# EFM32GG11B840F1024IQ100 register map
File version: 4.0.0
CPU: CM4 r0p1, little endian, MPU, FPU, 3 interrupt priority bits
Registers are 32-bit, read-write, reset 0x0 unless marked. A register's access mark holds for its fields unless they carry their own. Offsets are from the block's base; [hi:lo] are bit positions; {n}, {i} and the like mark numbered series.

## USART0
Base 0x40010000
Same registers: USART1 0x40010400, USART2 0x40010800, USART3 0x40010C00, USART4 0x40011000, USART5 0x40011400, UART0 0x40014000, UART1 0x40014400
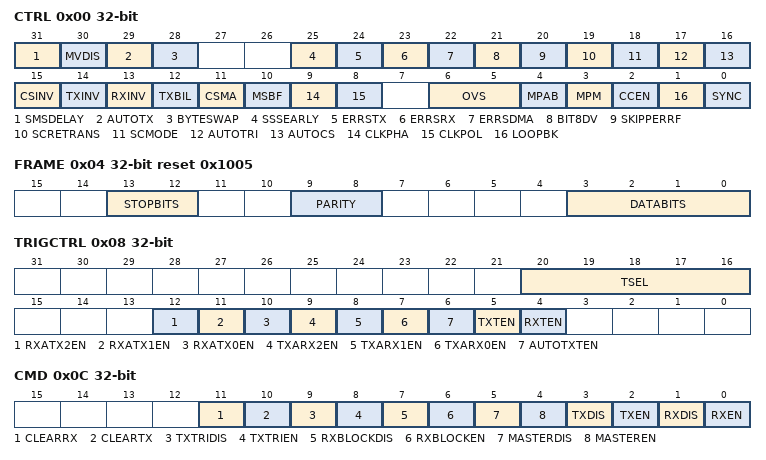
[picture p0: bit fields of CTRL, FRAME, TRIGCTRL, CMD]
0x00 CTRL — Control Register
  [31] SMSDELAY — Synchronous Master Sample Delay
  [30] MVDIS — Majority Vote Disable
  [29] AUTOTX — Always Transmit When RX Not Full
  [28] BYTESWAP — Byteswap in Double Accesses
  [25] SSSEARLY — Synchronous Slave Setup Early
  [24] ERRSTX — Disable TX on Error
  [23] ERRSRX — Disable RX on Error
  [22] ERRSDMA — Halt DMA on Error
  [21] BIT8DV — Bit 8 Default Value
  [20] SKIPPERRF — Skip Parity Error Frames
  [19] SCRETRANS — SmartCard Retransmit
  [18] SCMODE — SmartCard Mode
  [17] AUTOTRI — Automatic TX Tristate
  [16] AUTOCS — Automatic Chip Select
  [15] CSINV — Chip Select Invert
  [14] TXINV — Transmitter Output Invert
  [13] RXINV — Receiver Input Invert
  [12] TXBIL — TX Buffer Interrupt Level
  [11] CSMA — Action on Slave-Select in Master Mode
  [10] MSBF — Most Significant Bit First
  [9] CLKPHA — Clock Edge for Setup/Sample
  [8] CLKPOL — Clock Polarity
  [6:5] OVS — Oversampling
    0=X16 (Regular UART mode with 16X oversampling in asynchronous mode); 1=X8 (Double speed with 8X oversampling in asynchronous mode); 2=X6 (6X oversampling in asynchronous mode); 3=X4 (Quadruple speed with 4X oversampling in asynchronous mode)
  [4] MPAB — Multi-Processor Address-Bit
  [3] MPM — Multi-Processor Mode
  [2] CCEN — Collision Check Enable
  [1] LOOPBK — Loopback Enable
  [0] SYNC — USART Synchronous Mode
0x04 FRAME reset 0x1005 — USART Frame Format Register
  [13:12] STOPBITS — Stop-Bit Mode
    0=HALF (The transmitter generates a half stop bit. Stop-bits are not verified by receiver); 1=ONE (One stop bit is generated and verified); 2=ONEANDAHALF (The transmitter generates one and a half stop bit. The receiver verifies the first stop bit); 3=TWO (The transmitter generates two stop bits. The receiver checks the first stop-bit only)
  [9:8] PARITY — Parity-Bit Mode
    0=NONE (Parity bits are not used); 2=EVEN (Even parity are used. Parity bits are automatically generated and checked by hardware.); 3=ODD (Odd parity is used. Parity bits are automatically generated and checked by hardware.)
  [3:0] DATABITS — Data-Bit Mode
    1=FOUR (Each frame contains 4 data bits); 2=FIVE (Each frame contains 5 data bits); 3=SIX (Each frame contains 6 data bits); 4=SEVEN (Each frame contains 7 data bits); 5=EIGHT (Each frame contains 8 data bits); 6=NINE (Each frame contains 9 data bits); 7=TEN (Each frame contains 10 data bits); 8=ELEVEN (Each frame contains 11 data bits); 9=TWELVE (Each frame contains 12 data bits); 10=THIRTEEN (Each frame contains 13 data bits); 11=FOURTEEN (Each frame contains 14 data bits); 12=FIFTEEN (Each frame contains 15 data bits); 13=SIXTEEN (Each frame contains 16 data bits)
0x08 TRIGCTRL — USART Trigger Control Register
  [20:16] TSEL — Trigger PRS Channel Select
    {v}=PRSCH{v} (PRS Channel {v} selected) (v=0..23)
  [12] RXATX2EN — Enable Receive Trigger After TX End of Frame Plus TCMPVAL2 Baud-times
  [11] RXATX1EN — Enable Receive Trigger After TX End of Frame Plus TCMPVAL1 Baud-times
  [10] RXATX0EN — Enable Receive Trigger After TX End of Frame Plus TCMPVAL0 Baud-times
  [9] TXARX2EN — Enable Transmit Trigger After RX End of Frame Plus TCMP2VAL
  [8] TXARX1EN — Enable Transmit Trigger After RX End of Frame Plus TCMP1VAL
  [7] TXARX0EN — Enable Transmit Trigger After RX End of Frame Plus TCMP0VAL
  [6] AUTOTXTEN — AUTOTX Trigger Enable
  [5] TXTEN — Transmit Trigger Enable
  [4] RXTEN — Receive Trigger Enable
0x0C CMD wo — Command Register
  [11] CLEARRX
  [10] CLEARTX
  [9] TXTRIDIS — Transmitter Tristate Disable
  [8] TXTRIEN — Transmitter Tristate Enable
  [7] RXBLOCKDIS — Receiver Block Disable
  [6] RXBLOCKEN — Receiver Block Enable
  [5] MASTERDIS — Master Disable
  [4] MASTEREN — Master Enable
  [3] TXDIS — Transmitter Disable
  [2] TXEN — Transmitter Enable
  [1] RXDIS — Receiver Disable
  [0] RXEN — Receiver Enable
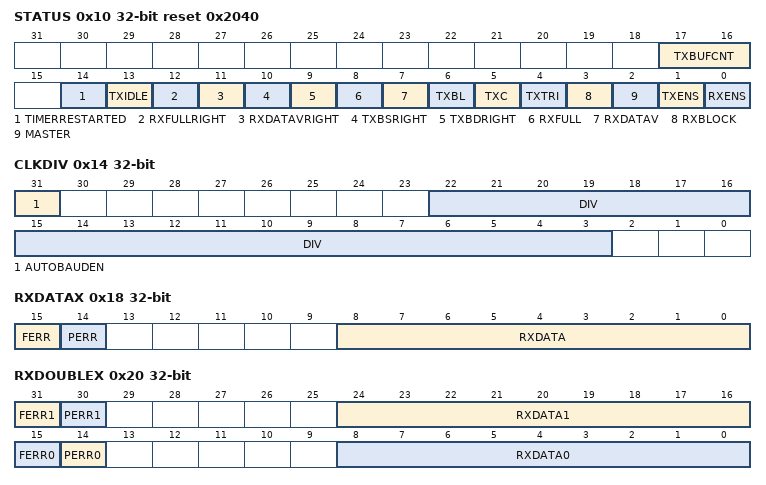
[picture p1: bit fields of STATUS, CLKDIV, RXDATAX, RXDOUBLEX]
0x10 STATUS ro reset 0x2040 — USART Status Register
  [17:16] TXBUFCNT — TX Buffer Count
  [14] TIMERRESTARTED — The USART Timer Restarted Itself
  [13] TXIDLE
  [12] RXFULLRIGHT — RX Full of Right Data
  [11] RXDATAVRIGHT — RX Data Right
  [10] TXBSRIGHT — TX Buffer Expects Single Right Data
  [9] TXBDRIGHT — TX Buffer Expects Double Right Data
  [8] RXFULL — RX FIFO Full
  [7] RXDATAV — RX Data Valid
  [6] TXBL — TX Buffer Level
  [5] TXC — TX Complete
  [4] TXTRI — Transmitter Tristated
  [3] RXBLOCK — Block Incoming Data
  [2] MASTER — SPI Master Mode
  [1] TXENS — Transmitter Enable Status
  [0] RXENS — Receiver Enable Status
0x14 CLKDIV — Clock Control Register
  [31] AUTOBAUDEN — AUTOBAUD Detection Enable
  [22:3] DIV — Fractional Clock Divider
0x18 RXDATAX ro read-has-side-effects — RX Buffer Data Extended Register
  [15] FERR — Data Framing Error
  [14] PERR — Data Parity Error
  [8:0] RXDATA
0x1C RXDATA ro read-has-side-effects — RX Buffer Data Register
  [7:0] RXDATA
0x20 RXDOUBLEX ro read-has-side-effects — RX Buffer Double Data Extended Register
  [31] FERR1 — Data Framing Error 1
  [30] PERR1 — Data Parity Error 1
  [24:16] RXDATA1
  [15] FERR0 — Data Framing Error 0
  [14] PERR0 — Data Parity Error 0
  [8:0] RXDATA0
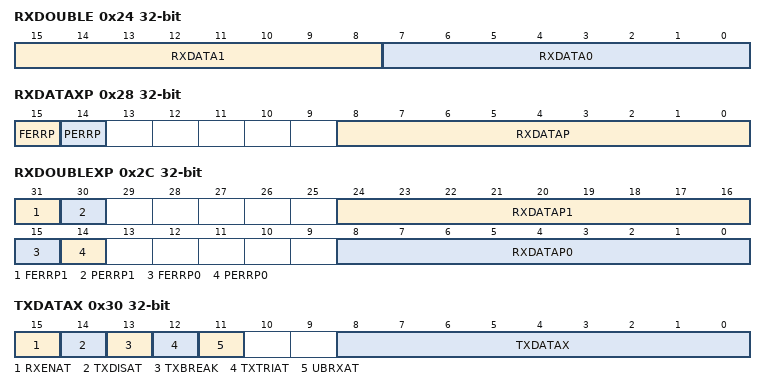
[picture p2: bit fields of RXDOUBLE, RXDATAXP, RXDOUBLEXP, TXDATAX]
0x24 RXDOUBLE ro read-has-side-effects — RX FIFO Double Data Register
  [15:8] RXDATA1, [7:0] RXDATA0
0x28 RXDATAXP ro — RX Buffer Data Extended Peek Register
  [15] FERRP — Data Framing Error Peek
  [14] PERRP — Data Parity Error Peek
  [8:0] RXDATAP — RX Data Peek
0x2C RXDOUBLEXP ro — RX Buffer Double Data Extended Peek Register
  [31] FERRP1 — Data Framing Error 1 Peek
  [30] PERRP1 — Data Parity Error 1 Peek
  [24:16] RXDATAP1 — RX Data 1 Peek
  [15] FERRP0 — Data Framing Error 0 Peek
  [14] PERRP0 — Data Parity Error 0 Peek
  [8:0] RXDATAP0 — RX Data 0 Peek
0x30 TXDATAX — TX Buffer Data Extended Register
  [15] RXENAT — Enable RX After Transmission
  [14] TXDISAT — Clear TXEN After Transmission
  [13] TXBREAK — Transmit Data as Break
  [12] TXTRIAT — Set TXTRI After Transmission
  [11] UBRXAT — Unblock RX After Transmission
  [8:0] TXDATAX — TX Data
0x34 TXDATA — TX Buffer Data Register
  [7:0] TXDATA
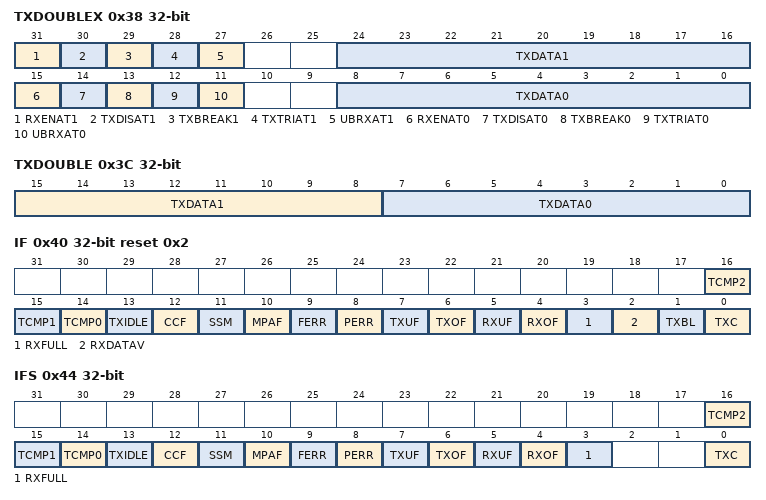
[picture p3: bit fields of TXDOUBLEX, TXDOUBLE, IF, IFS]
0x38 TXDOUBLEX — TX Buffer Double Data Extended Register
  [31] RXENAT1 — Enable RX After Transmission
  [30] TXDISAT1 — Clear TXEN After Transmission
  [29] TXBREAK1 — Transmit Data as Break
  [28] TXTRIAT1 — Set TXTRI After Transmission
  [27] UBRXAT1 — Unblock RX After Transmission
  [24:16] TXDATA1 — TX Data
  [15] RXENAT0 — Enable RX After Transmission
  [14] TXDISAT0 — Clear TXEN After Transmission
  [13] TXBREAK0 — Transmit Data as Break
  [12] TXTRIAT0 — Set TXTRI After Transmission
  [11] UBRXAT0 — Unblock RX After Transmission
  [8:0] TXDATA0 — TX Data
0x3C TXDOUBLE — TX Buffer Double Data Register
  [15:8] TXDATA1 — TX Data
  [7:0] TXDATA0 — TX Data
0x40 IF ro reset 0x2 — Interrupt Flag Register
  [16] TCMP2 — Timer Comparator 2 Interrupt Flag
  [15] TCMP1 — Timer Comparator 1 Interrupt Flag
  [14] TCMP0 — Timer Comparator 0 Interrupt Flag
  [13] TXIDLE — TX Idle Interrupt Flag
  [12] CCF — Collision Check Fail Interrupt Flag
  [11] SSM — Slave-Select in Master Mode Interrupt Flag
  [10] MPAF — Multi-Processor Address Frame Interrupt Flag
  [9] FERR — Framing Error Interrupt Flag
  [8] PERR — Parity Error Interrupt Flag
  [7] TXUF — TX Underflow Interrupt Flag
  [6] TXOF — TX Overflow Interrupt Flag
  [5] RXUF — RX Underflow Interrupt Flag
  [4] RXOF — RX Overflow Interrupt Flag
  [3] RXFULL — RX Buffer Full Interrupt Flag
  [2] RXDATAV — RX Data Valid Interrupt Flag
  [1] TXBL — TX Buffer Level Interrupt Flag
  [0] TXC — TX Complete Interrupt Flag
0x44 IFS wo — Interrupt Flag Set Register
  [16] TCMP2 — Set TCMP2 Interrupt Flag
  [15] TCMP1 — Set TCMP1 Interrupt Flag
  [14] TCMP0 — Set TCMP0 Interrupt Flag
  [13] TXIDLE — Set TXIDLE Interrupt Flag
  [12] CCF — Set CCF Interrupt Flag
  [11] SSM — Set SSM Interrupt Flag
  [10] MPAF — Set MPAF Interrupt Flag
  [9] FERR — Set FERR Interrupt Flag
  [8] PERR — Set PERR Interrupt Flag
  [7] TXUF — Set TXUF Interrupt Flag
  [6] TXOF — Set TXOF Interrupt Flag
  [5] RXUF — Set RXUF Interrupt Flag
  [4] RXOF — Set RXOF Interrupt Flag
  [3] RXFULL — Set RXFULL Interrupt Flag
  [0] TXC — Set TXC Interrupt Flag
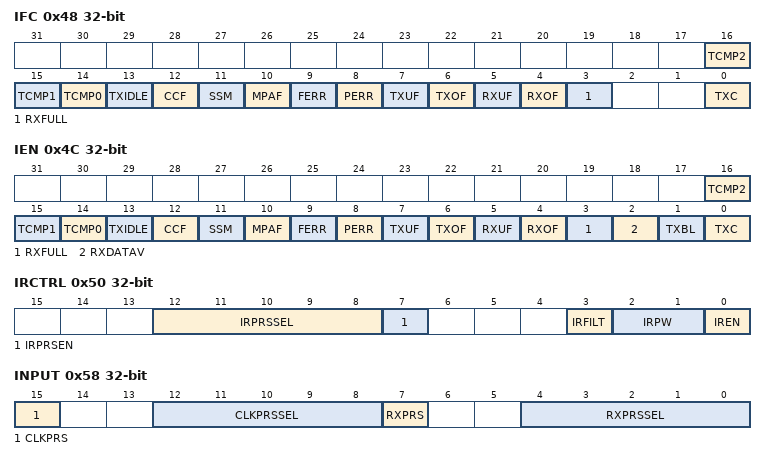
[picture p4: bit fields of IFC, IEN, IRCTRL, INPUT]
0x48 IFC wo — Interrupt Flag Clear Register
  [16] TCMP2 — Clear TCMP2 Interrupt Flag
  [15] TCMP1 — Clear TCMP1 Interrupt Flag
  [14] TCMP0 — Clear TCMP0 Interrupt Flag
  [13] TXIDLE — Clear TXIDLE Interrupt Flag
  [12] CCF — Clear CCF Interrupt Flag
  [11] SSM — Clear SSM Interrupt Flag
  [10] MPAF — Clear MPAF Interrupt Flag
  [9] FERR — Clear FERR Interrupt Flag
  [8] PERR — Clear PERR Interrupt Flag
  [7] TXUF — Clear TXUF Interrupt Flag
  [6] TXOF — Clear TXOF Interrupt Flag
  [5] RXUF — Clear RXUF Interrupt Flag
  [4] RXOF — Clear RXOF Interrupt Flag
  [3] RXFULL — Clear RXFULL Interrupt Flag
  [0] TXC — Clear TXC Interrupt Flag
0x4C IEN — Interrupt Enable Register
  [16] TCMP2 — TCMP2 Interrupt Enable
  [15] TCMP1 — TCMP1 Interrupt Enable
  [14] TCMP0 — TCMP0 Interrupt Enable
  [13] TXIDLE — TXIDLE Interrupt Enable
  [12] CCF — CCF Interrupt Enable
  [11] SSM — SSM Interrupt Enable
  [10] MPAF — MPAF Interrupt Enable
  [9] FERR — FERR Interrupt Enable
  [8] PERR — PERR Interrupt Enable
  [7] TXUF — TXUF Interrupt Enable
  [6] TXOF — TXOF Interrupt Enable
  [5] RXUF — RXUF Interrupt Enable
  [4] RXOF — RXOF Interrupt Enable
  [3] RXFULL — RXFULL Interrupt Enable
  [2] RXDATAV — RXDATAV Interrupt Enable
  [1] TXBL — TXBL Interrupt Enable
  [0] TXC — TXC Interrupt Enable
0x50 IRCTRL — IrDA Control Register
  [12:8] IRPRSSEL — IrDA PRS Channel Select
    {v}=PRSCH{v} (PRS Channel {v} selected) (v=0..23)
  [7] IRPRSEN — IrDA PRS Channel Enable
  [3] IRFILT — IrDA RX Filter
  [2:1] IRPW — IrDA TX Pulse Width
    0=ONE (IrDA pulse width is 1/16 for OVS=0 and 1/8 for OVS=1); 1=TWO (IrDA pulse width is 2/16 for OVS=0 and 2/8 for OVS=1); 2=THREE (IrDA pulse width is 3/16 for OVS=0 and 3/8 for OVS=1); 3=FOUR (IrDA pulse width is 4/16 for OVS=0 and 4/8 for OVS=1)
  [0] IREN — Enable IrDA Module
0x58 INPUT — USART Input Register
  [15] CLKPRS — PRS CLK Enable
  [12:8] CLKPRSSEL — CLK PRS Channel Select
    {v}=PRSCH{v} (PRS Channel {v} selected) (v=0..23)
  [7] RXPRS — PRS RX Enable
  [4:0] RXPRSSEL — RX PRS Channel Select
    {v}=PRSCH{v} (PRS Channel {v} selected) (v=0..23)
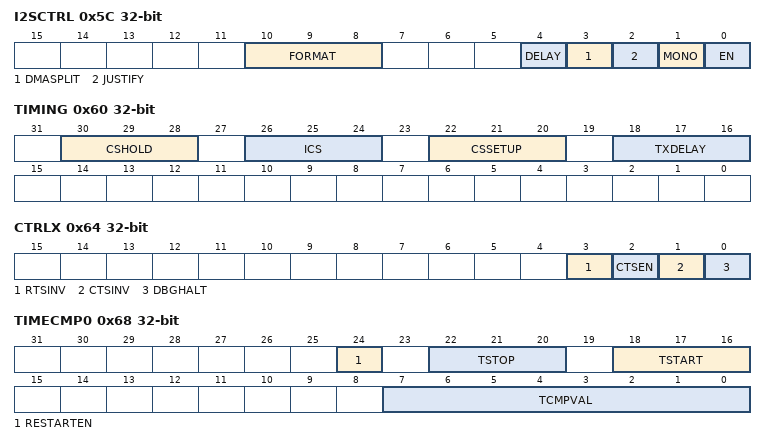
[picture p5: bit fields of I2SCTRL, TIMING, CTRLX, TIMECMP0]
0x5C I2SCTRL — I2S Control Register
  [10:8] FORMAT — I2S Word Format
    0=W32D32 (32-bit word, 32-bit data); 1=W32D24M (32-bit word, 32-bit data with 8 lsb masked); 2=W32D24 (32-bit word, 24-bit data); 3=W32D16 (32-bit word, 16-bit data); 4=W32D8 (32-bit word, 8-bit data); 5=W16D16 (16-bit word, 16-bit data); 6=W16D8 (16-bit word, 8-bit data); 7=W8D8 (8-bit word, 8-bit data)
  [4] DELAY — Delay on I2S Data
  [3] DMASPLIT — Separate DMA Request for Left/Right Data
  [2] JUSTIFY — Justification of I2S Data
  [1] MONO — Stero or Mono
  [0] EN — Enable I2S Mode
0x60 TIMING
  [30:28] CSHOLD — Chip Select Hold
    0=ZERO (Disable CS being asserted after the end of transmission); 1=ONE (CS is asserted for 1 baud-times after the end of transmission); 2=TWO (CS is asserted for 2 baud-times after the end of transmission); 3=THREE (CS is asserted for 3 baud-times after the end of transmission); 4=SEVEN (CS is asserted for 7 baud-times after the end of transmission); 5=TCMP0 (CS is asserted after the end of transmission for TCMPVAL0 baud-times); 6=TCMP1 (CS is asserted after the end of transmission for TCMPVAL1 baud-times); 7=TCMP2 (CS is asserted after the end of transmission for TCMPVAL2 baud-times)
  [26:24] ICS — Inter-character Spacing
    0=ZERO (There is no space between charcters); 1=ONE (Create a space of 1 baud-times before start of transmission); 2=TWO (Create a space of 2 baud-times before start of transmission); 3=THREE (Create a space of 3 baud-times before start of transmission); 4=SEVEN (Create a space of 7 baud-times before start of transmission); 5=TCMP0 (Create a space of before the start of transmission for TCMPVAL0 baud-times); 6=TCMP1 (Create a space of before the start of transmission for TCMPVAL1 baud-times); 7=TCMP2 (Create a space of before the start of transmission for TCMPVAL2 baud-times)
  [22:20] CSSETUP — Chip Select Setup
    0=ZERO (CS is not asserted before start of transmission); 1=ONE (CS is asserted for 1 baud-times before start of transmission); 2=TWO (CS is asserted for 2 baud-times before start of transmission); 3=THREE (CS is asserted for 3 baud-times before start of transmission); 4=SEVEN (CS is asserted for 7 baud-times before start of transmission); 5=TCMP0 (CS is asserted before the start of transmission for TCMPVAL0 baud-times); 6=TCMP1 (CS is asserted before the start of transmission for TCMPVAL1 baud-times); 7=TCMP2 (CS is asserted before the start of transmission for TCMPVAL2 baud-times)
  [18:16] TXDELAY — TX Frame Start Delay
    0=DISABLE (Disable - TXDELAY in USARTn_CTRL can be used for legacy); 1=ONE (Start of transmission is delayed for 1 baud-times); 2=TWO (Start of transmission is delayed for 2 baud-times); 3=THREE (Start of transmission is delayed for 3 baud-times); 4=SEVEN (Start of transmission is delayed for 7 baud-times); 5=TCMP0 (Start of transmission is delayed for TCMPVAL0 baud-times); 6=TCMP1 (Start of transmission is delayed for TCMPVAL1 baud-times); 7=TCMP2 (Start of transmission is delayed for TCMPVAL2 baud-times)
0x64 CTRLX — Control Register Extended
  [3] RTSINV — RTS Pin Inversion
  [2] CTSEN — CTS Function Enabled
  [1] CTSINV — CTS Pin Inversion
  [0] DBGHALT — Debug Halt
0x68 TIMECMP0 — Used to Generate Interrupts and Various Delays
  [24] RESTARTEN — Restart Timer on TCMP0
  [22:20] TSTOP — Source Used to Disable Comparator 0
    0=TCMP0 (Comparator 0 is disabled when the counter equals TCMPVAL and triggers a TCMP0 event); 1=TXST (Comparator 0 is disabled at the start of transmission); 2=RXACT (Comparator 0 is disabled on RX going going Active (default: low)); 3=RXACTN (Comparator 0 is disabled on RX going Inactive)
  [18:16] TSTART — Timer Start Source
    0=DISABLE (Comparator 0 is disabled); 1=TXEOF (Comparator 0 and timer are started at TX end of frame); 2=TXC (Comparator 0 and timer are started at TX Complete); 3=RXACT (Comparator 0 and timer are started at RX going Active (default: low)); 4=RXEOF (Comparator 0 and timer are started at RX end of frame)
  [7:0] TCMPVAL — Timer Comparator 0
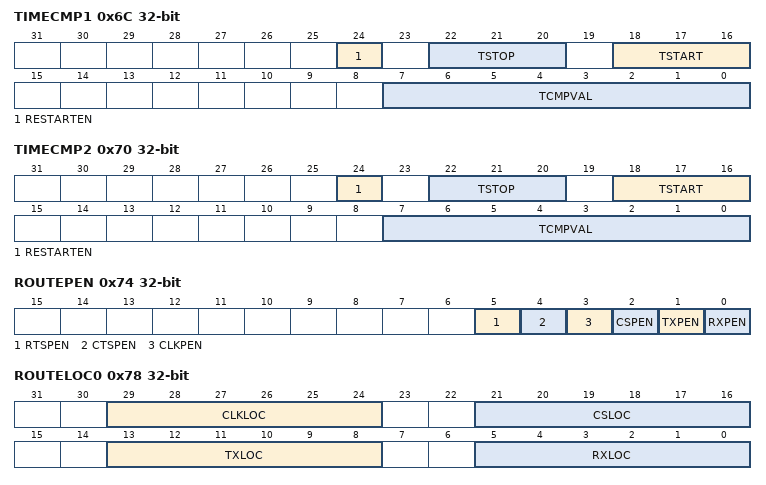
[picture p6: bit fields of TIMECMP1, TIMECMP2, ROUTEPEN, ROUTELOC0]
0x6C TIMECMP1 — Used to Generate Interrupts and Various Delays
  [24] RESTARTEN — Restart Timer on TCMP1
  [22:20] TSTOP — Source Used to Disable Comparator 1
    0=TCMP1 (Comparator 1 is disabled when the counter equals TCMPVAL and triggers a TCMP1 event); 1=TXST (Comparator 1 is disabled at TX start TX Engine); 2=RXACT (Comparator 1 is disabled on RX going going Active (default: low)); 3=RXACTN (Comparator 1 is disabled on RX going Inactive)
  [18:16] TSTART — Timer Start Source
    0=DISABLE (Comparator 1 is disabled); 1=TXEOF (Comparator 1 and timer are started at TX end of frame); 2=TXC (Comparator 1 and timer are started at TX Complete); 3=RXACT (Comparator 1 and timer are started at RX going going Active (default: low)); 4=RXEOF (Comparator 1 and timer are started at RX end of frame)
  [7:0] TCMPVAL — Timer Comparator 1
0x70 TIMECMP2 — Used to Generate Interrupts and Various Delays
  [24] RESTARTEN — Restart Timer on TCMP2
  [22:20] TSTOP — Source Used to Disable Comparator 2
    0=TCMP2 (Comparator 2 is disabled when the counter equals TCMPVAL and triggers a TCMP2 event); 1=TXST (Comparator 2 is disabled at TX start TX Engine); 2=RXACT (Comparator 2 is disabled on RX going going Active (default: low)); 3=RXACTN (Comparator 2 is disabled on RX going Inactive)
  [18:16] TSTART — Timer Start Source
    0=DISABLE (Comparator 2 is disabled); 1=TXEOF (Comparator 2 and timer are started at TX end of frame); 2=TXC (Comparator 2 and timer are started at TX Complete); 3=RXACT (Comparator 2 and timer are started at RX going going Active (default: low)); 4=RXEOF (Comparator 2 and timer are started at RX end of frame)
  [7:0] TCMPVAL — Timer Comparator 2
0x74 ROUTEPEN — I/O Routing Pin Enable Register
  [5] RTSPEN — RTS Pin Enable
  [4] CTSPEN — CTS Pin Enable
  [3] CLKPEN — CLK Pin Enable
  [2] CSPEN — CS Pin Enable
  [1] TXPEN — TX Pin Enable
  [0] RXPEN — RX Pin Enable
0x78 ROUTELOC0 — I/O Routing Location Register
  [all] fields
    {v}=LOC{v} (Location {v}) (v=0..6)
  [29:24] CLKLOC — I/O Location
  [21:16] CSLOC — I/O Location
  [13:8] TXLOC — I/O Location
  [5:0] RXLOC — I/O Location
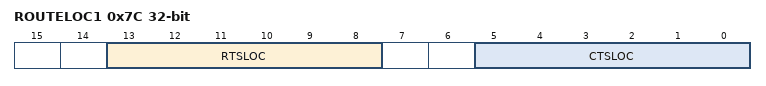
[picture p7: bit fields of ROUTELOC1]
0x7C ROUTELOC1 — I/O Routing Location Register
  [13:8] RTSLOC — I/O Location
    {v}=LOC{v} (Location {v}) (v=0..6)
  [5:0] CTSLOC — I/O Location
    {v}=LOC{v} (Location {v}) (v=0..6)

## Notices in the file
# License
Copyright 2021 Silicon Laboratories Inc. www.silabs.com
SPDX-License-Identifier: Zlib
The licensor of this software is Silicon Laboratories Inc.
This software is provided 'as-is', without any express or implied
warranty. In no event will the authors be held liable for any damages
arising from the use of this software.
Permission is granted to anyone to use this software for any purpose,
including commercial applications, and to alter it and redistribute it
freely, subject to the following restrictions:
1. The origin of this software must not be misrepresented; you must not
claim that you wrote the original software. If you use this software
in a product, an acknowledgment in the product documentation would be
appreciated but is not required.
2. Altered source versions must be plainly marked as such, and must not be
misrepresented as being the original software.
3. This notice may not be removed or altered from any source distribution.
